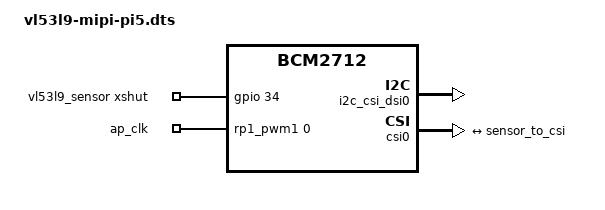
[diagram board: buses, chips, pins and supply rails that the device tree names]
// SPDX-License-Identifier: GPL-2.0-only
/*
 * VL53L9CX time-of-flight lidar (STEVAL-VL53L9) on Raspberry Pi 5 (BCM2712 + RP1).
 *
 * The VL53L9CX streams a RAW8 (datatype 0x2A, single data lane) MIPI CSI-2 image of
 * the ranging results and is configured over the camera connector I2C bus by
 * userspace (app/vl53l9_bringup). The kernel side needs:
 *   - the RP1 CSI receiver (CFE) enabled with a 1-lane endpoint,
 *   - the connector I2C bus enabled so userspace can talk to the sensor,
 *   - a dummy CSI-2 sensor subdevice node matched by driver/dummy_cam.ko,
 *   - the sensor's control signals, all over the stock STEVAL flex cable.
 *
 * Port: CAM/DISP 0 (MIPI0: csi0 + i2c_csi_dsi0 -> /dev/i2c-6) only. The XSHUT and
 * AP_CLK lines below are MIPI0 connector pins. Enable with:
 *     dtoverlay=vl53l9-mipi-pi5        (",cam0" is accepted for compatibility)
 *
 * Control signals (MIPI0 connector -> STEVAL-VL53L9):
 *   pin 17  CD0_IO0  RP1 GPIO34  -> XSHUT. Must be HIGH for the sensor to run;
 *                                   LOW = shutdown. Owned by dummy_cam.ko, which
 *                                   holds it LOW at boot and exposes
 *                                   /sys/devices/platform/vl53l9/xshut_cycle.
 *   pin 18  CD0_IO1  RP1 GPIO35  -> AP_CLK, 12 MHz from PWM1 channel 0. The
 *                                   STEVAL ships with its on-board oscillator
 *                                   disabled, so the host must supply it.
 * There is no power-enable net: the sensor rails come from the connector's 3V3.
 */
#include <dt-bindings/gpio/gpio.h>

/dts-v1/;
/plugin/;

/ {
	compatible = "brcm,bcm2712";

	i2c_frag: fragment@0 {
		target = <&i2c_csi_dsi0>;
		__overlay__ {
			status = "okay";
		};
	};

	csi_frag: fragment@1 {
		target = <&csi0>;
		__overlay__ {
			status = "okay";

			port {
				csi_to_sensor: endpoint {
					remote-endpoint = <&sensor_to_csi>;
					clock-lanes = <0>;
					data-lanes = <1>;  /* VL53L9CX: single data lane */
				};
			};
		};
	};

	sensor_frag: fragment@2 {
		target-path = "/";
		__overlay__ {
			vl53l9_sensor: vl53l9 {
				compatible = "raspberrypi,dummy-csi2-sensor";
				status = "okay";

				/* XSHUT (see header). The sensor's ROM boots to
				 * READY_TO_BOOT after a LOW -> HIGH edge. */
				xshut-gpios = <&gpio 34 GPIO_ACTIVE_HIGH>;

				/* AP_CLK. GPIO35 can only output PWM1 channel 0. PWM1 runs from
				 * 96 MHz (fragment@5); the counter runs 0..range, so
				 * 12 MHz needs range=7 (8 ticks). The rpi-pwm driver
				 * rounds period*100MHz, so request 70 ns (-> range 7)
				 * and 42 ns duty (-> 4 ticks, 50%). It must be exactly
				 * 12 MHz: 10.67 MHz makes the firmware fault on start. */
				pwms = <&rp1_pwm1 0 70 0>;
				pwm-names = "ap_clk";
				ap-clk-duty-ns = <42>;
				pinctrl-names = "default";
				pinctrl-0 = <&vl53l9_apclk_pins>;

				port {
					sensor_to_csi: endpoint {
						remote-endpoint = <&csi_to_sensor>;
					};
				};
			};
		};
	};

	cam0reg_frag: fragment@3 {
		target = <&cam0_reg>;
		__overlay__ {
			/* The baseboard defines line 34 as a camera-rail enable; on this
			 * module it is XSHUT. Left active, the regulator would claim the
			 * GPIO so dummy_cam.ko could not use it as xshut-gpios. */
			status = "disabled";
		};
	};

	/* Route GPIO35 (CD0_IO1) to PWM1 channel 0 for AP_CLK. */
	apclk_frag: fragment@4 {
		target = <&rp1_gpio>;
		__overlay__ {
			vl53l9_apclk_pins: vl53l9_apclk_pins {
				function = "pwm1";
				pins = "gpio35";
				bias-disable;
			};
		};
	};

	/* Clock PWM1 at 96 MHz from the (otherwise unused) video PLL:
	 * 960 MHz VCO / 10 = 96 MHz; 96 MHz / 8 = 12 MHz exactly.
	 * IDs: 2 = RP1_PLL_VIDEO_CORE, 11 = RP1_PLL_VIDEO_SEC, 18 = RP1_CLK_PWM1.
	 * The fan on PWM1 channel 3 keeps working. */
	pwmclk_frag: fragment@5 {
		target = <&rp1_pwm1>;
		__overlay__ {
			assigned-clocks = <&rp1_clocks 2>, <&rp1_clocks 11>,
					  <&rp1_clocks 18>;
			assigned-clock-parents = <0>, <0>, <&rp1_clocks 11>;
			assigned-clock-rates = <960000000>, <96000000>,
					       <96000000>;
		};
	};

	/* "cam0" is kept so existing "dtoverlay=vl53l9-mipi-pi5,cam0" lines still
	 * work; it re-selects the MIPI0 targets that are already the default. */
	__overrides__ {
		cam0 = <&i2c_frag>, "target:0=", <&i2c_csi_dsi0>,
		       <&csi_frag>, "target:0=", <&csi0>;
	};
};
